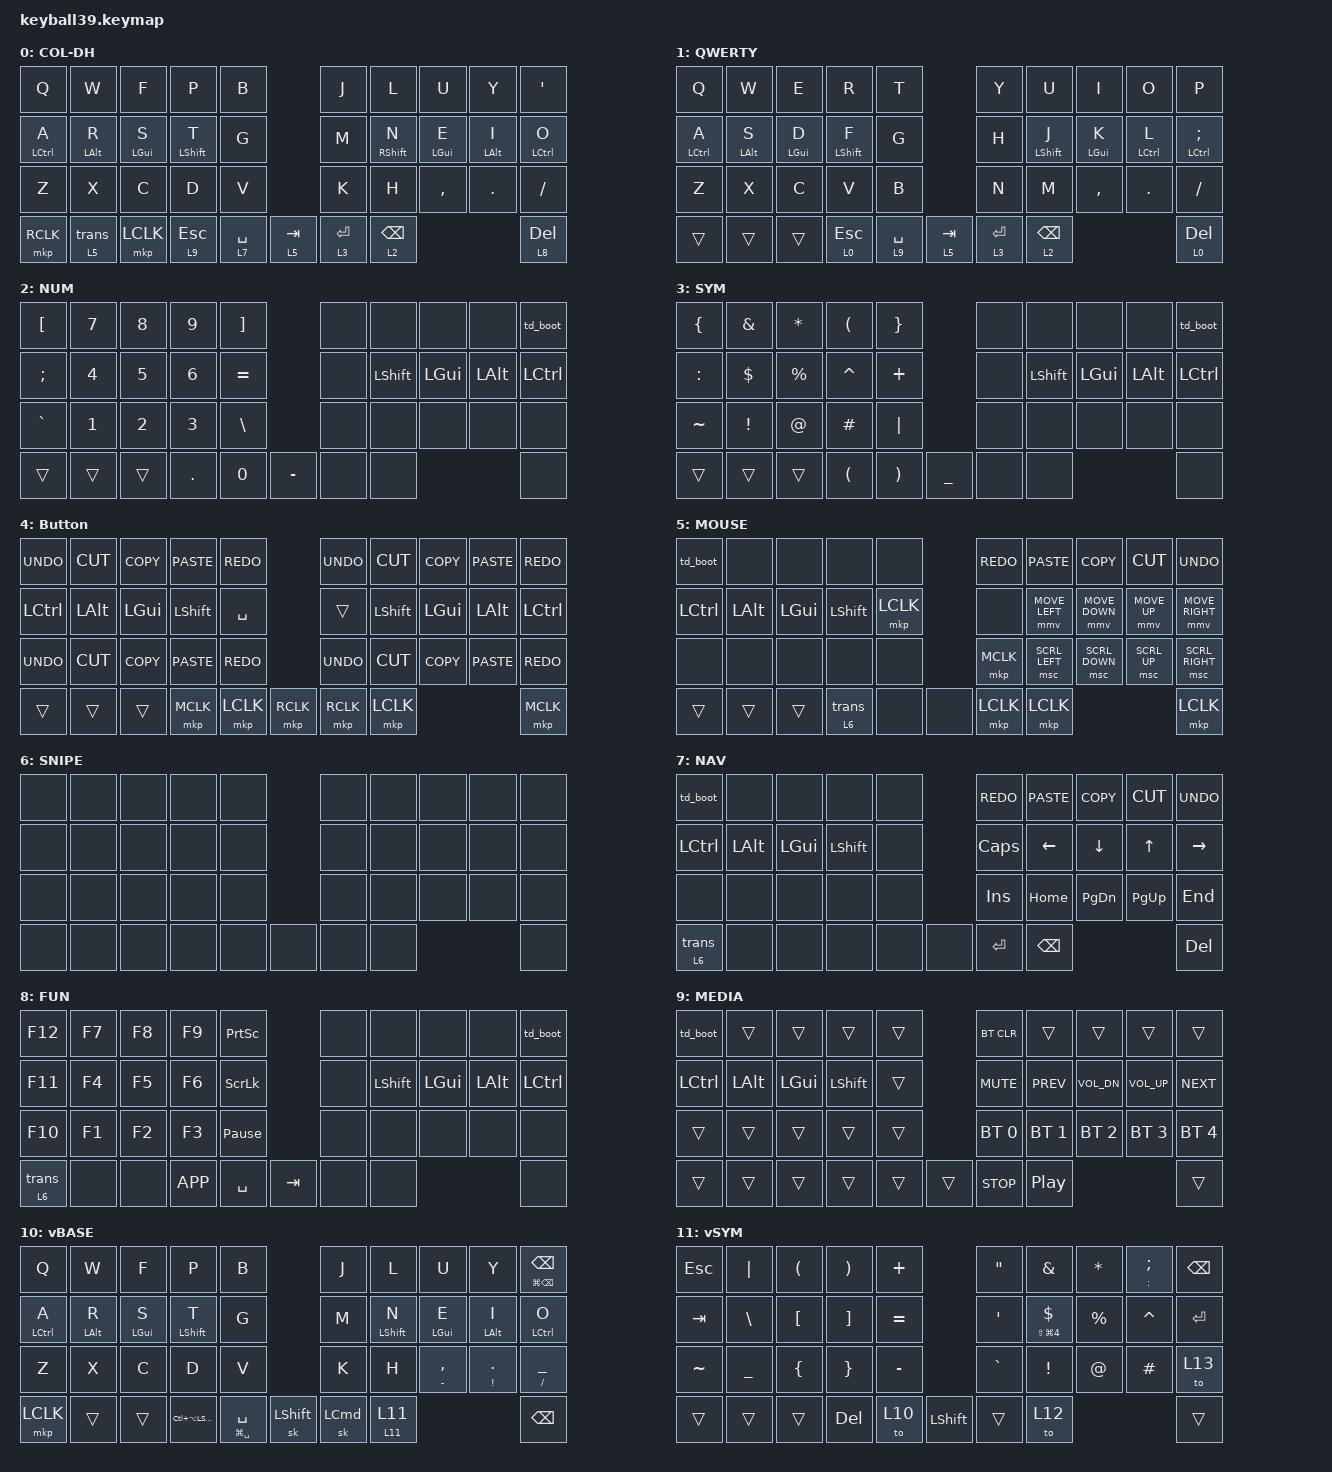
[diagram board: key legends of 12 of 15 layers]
//ZMK configs

#include <behaviors/mouse_keys.dtsi>
#include <dt-bindings/zmk/mouse.h>
#include <behaviors.dtsi>
#include <dt-bindings/zmk/bt.h>
#include <dt-bindings/zmk/keys.h>
#include <dt-bindings/zmk/pointing.h>

// Personal configs

#define HM_TAPPING_TERM 250
#define HM_TAPPING_TERM_FAST 180
#define HM_PRIOR_IDLE 120
#define XXX &none
#define ___ &trans
#define DEFAULT 0  // Colmak Mod-DH
#define QWERTY  1  // QWERTY Alternative
#define NUM     2  // Numbers and related symbols
#define SYM     3  // Symbols mapped similarly to numbers
#define BUTTON  4  // Button layer in conjunction with a mouse or input device
#define MOUSE   5  // Mouse layer also used as a scroll layer
#define SNIPE   6  // Snipe layer for more precise cursor control
#define NAV     7  // Navigation layer for arrow keys and navigation keys
#define FUN     8  // Function layer for function keys
#define MEDIA   9  // Media layer for media control keys

/* Global defaults */

#define QUICK_TAP_MS 175

&sk {
    release-after-ms = <900>;
    quick-release;
};

&sl { ignore-modifiers; };

&lt {
    flavor = "balanced";
    tapping-term-ms = <200>;
    quick-tap-ms = <QUICK_TAP_MS>;
};

/ {
    // custom shift using mod-morph 

    behaviors {
        bt_clr_dbl: bluetooth_clear {
            compatible = "zmk,behavior-tap-dance";
            label = "Clear bluetooth profile";
            #binding-cells = <0>;
            bindings = <&none>, <&bt BT_CLR>;
        };

        td_boot: double_tap_bootloader {
            compatible = "zmk,behavior-tap-dance";
            label = "Double Tap Bootloader";
            #binding-cells = <0>;
            bindings = <&none>, <&bootloader>;
        };

        ht_layertrans: ht_layertrans {
            compatible = "zmk,behavior-hold-tap";
            label = "Switches to Layer on Hold, Trans on Tap";
            bindings = <&mo>, <&trans>;

            #binding-cells = <2>;
            tapping-term-ms = <200>;
        };

        hrm_l: homerow_mod_left {
            compatible = "zmk,behavior-hold-tap";
            label = "Homerow Mod - Left";
            bindings = <&kp>, <&kp>;

            #binding-cells = <2>;
            tapping-term-ms = <250>;
            quick-tap-ms = <175>;
            require-prior-idle-ms = <120>;
            flavor = "balanced";
            hold-trigger-key-positions = <5 6 7 8 9 15 16 17 18 19 25 26 27 28 29 36 37 38 35 34 33 32 31 30>;
            hold-trigger-on-release;
        };

        hrm_r: homerow_mod_right {
            compatible = "zmk,behavior-hold-tap";
            label = "Homerow Mod - Right";
            bindings = <&kp>, <&kp>;

            #binding-cells = <2>;
            tapping-term-ms = <250>;
            quick-tap-ms = <175>;
            require-prior-idle-ms = <120>;
            flavor = "balanced";
            hold-trigger-on-release;
            hold-trigger-key-positions = <0 1 2 3 4 10 11 12 13 14 20 21 22 23 24 30 31 32 33 34 35 38 37 36>;
        };

        hrm_shift_l: homerow_mod_shift_left {
            compatible = "zmk,behavior-hold-tap";
            label = "Homerow Mod - Shift - Left";
            bindings = <&kp>, <&kp>;

            #binding-cells = <2>;
            tapping-term-ms = <180>;
            quick-tap-ms = <175>;
            require-prior-idle-ms = <120>;
            flavor = "balanced";
            hold-trigger-key-positions = <5 6 7 8 9 15 16 17 18 19 25 26 27 28 29 36 37 38 35 34 33 32 31 30>;
        };

        hrm_shift_r: homerow_mod_shift_right {
            compatible = "zmk,behavior-hold-tap";
            label = "Homerow Mod - Shift - Right";
            bindings = <&kp>, <&kp>;

            #binding-cells = <2>;
            tapping-term-ms = <180>;
            quick-tap-ms = <175>;
            require-prior-idle-ms = <120>;
            flavor = "balanced";
            hold-trigger-key-positions = <0 1 2 3 4 10 11 12 13 14 20 21 22 23 24 30 31 32 33 34 35 36 37 38>;
        };

        ht_holdto_tapsticky: ht_holdto_tapsticky {
            compatible = "zmk,behavior-hold-tap";
            label = "Hold Tap (to layer, sticky layer)";
            bindings = <&to>, <&sl>;

            #binding-cells = <2>;
            tapping-term-ms = <250>;
            flavor = "tap-preferred";
            quick-tap-ms = <175>;
            require-prior-idle-ms = <120>;
        };
    };

    keymap {
        compatible = "zmk,keymap";

        miryoku_alpha_colmak {
            label = "COL-DH";
            bindings = <
&kp Q           &kp W               &kp F          &kp P                  &kp B                                &kp J            &kp L                  &kp U          &kp Y          &kp APOS
&hrm_l LCTRL A  &hrm_l LALT R       &hrm_l LGUI S  &hrm_shift_l LSHIFT T  &kp G                                &kp M            &hrm_shift_r RSHIFT N  &hrm_r LGUI E  &hrm_r LALT I  &hrm_r LCTRL O
&kp Z           &kp X               &kp C          &kp D                  &kp V                                &kp K            &kp H                  &kp COMMA      &kp DOT        &kp FSLH
&mkp RCLK       &ht_layertrans 5 0  &mkp LCLK      &lt 9 ESCAPE           &lt 7 SPACE  &lt 5 TAB  &lt 3 ENTER  &lt 2 BACKSPACE                                                       &lt 8 DEL
            >;
        };

        miryoku_alpha_qwerty {
            label = "QWERTY";
            bindings = <
&kp Q           &kp W          &kp E          &kp R                  &kp T                                &kp Y            &kp U                  &kp I          &kp O           &kp P
&hrm_l LCTRL A  &hrm_l LALT S  &hrm_l LGUI D  &hrm_shift_l LSHIFT F  &kp G                                &kp H            &hrm_shift_r LSHIFT J  &hrm_r LGUI K  &hrm_r LCTRL L  &hrm_r LCTRL SEMICOLON
&kp Z           &kp X          &kp C          &kp V                  &kp B                                &kp N            &kp M                  &kp COMMA      &kp DOT         &kp FSLH
&trans          &trans         &trans         &lt 0 ESCAPE           &lt 9 SPACE  &lt 5 TAB  &lt 3 ENTER  &lt 2 BACKSPACE                                                        &lt 0 DEL
            >;
        };

        miryoku_num {
            label = "NUM";
            bindings = <
&kp LBKT   &kp N7  &kp N8  &kp N9   &kp RBKT                     &none  &none      &none     &none     &td_boot
&kp SEMI   &kp N4  &kp N5  &kp N6   &kp EQUAL                    &none  &kp LSHFT  &kp LGUI  &kp LALT  &kp LCTRL
&kp GRAVE  &kp N1  &kp N2  &kp N3   &kp BSLH                     &none  &none      &none     &none     &none
&trans     &trans  &trans  &kp DOT  &kp N0     &kp MINUS  &none  &none                                 &none
            >;
        };

        miryoku_sym {
            label = "SYM";
            bindings = <
&kp LBRC   &kp AMPS  &kp ASTRK  &kp LPAR   &kp RBRC                    &none  &none      &none     &none     &td_boot
&kp COLON  &kp DLLR  &kp PRCNT  &kp CARET  &kp PLUS                    &none  &kp LSHFT  &kp LGUI  &kp LALT  &kp LCTRL
&kp TILDE  &kp EXCL  &kp AT     &kp HASH   &kp PIPE                    &none  &none      &none     &none     &none
&trans     &trans    &trans     &kp LPAR   &kp RPAR  &kp UNDER  &none  &none                                 &none
            >;
        };

        miryoku_button {
            bindings = <
&kp K_UNDO  &kp K_CUT     &kp K_COPY  &kp K_PASTE  &kp K_REDO                        &kp K_UNDO  &kp K_CUT  &kp K_COPY  &kp K_PASTE   &kp K_REDO
&kp LCTRL   &kp LEFT_ALT  &kp LGUI    &kp LSHFT    &kp SPACE                         &trans      &kp LSHFT  &kp LGUI    &kp LEFT_ALT  &kp LCTRL
&kp K_UNDO  &kp K_CUT     &kp K_COPY  &kp K_PASTE  &kp K_REDO                        &kp K_UNDO  &kp K_CUT  &kp K_COPY  &kp K_PASTE   &kp K_REDO
&trans      &trans        &trans      &mkp MCLK    &mkp LCLK   &mkp RCLK  &mkp RCLK  &mkp LCLK                                        &mkp MCLK
            >;

            label = "Button";
        };

        miryoku_mouse {
            label = "MOUSE";
            bindings = <
&td_boot   &none         &none     &none               &none                        &kp K_REDO  &kp K_PASTE     &kp K_COPY      &kp K_CUT     &kp K_UNDO
&kp LCTRL  &kp LEFT_ALT  &kp LGUI  &kp LSHFT           &mkp LCLK                    &none       &mmv MOVE_LEFT  &mmv MOVE_DOWN  &mmv MOVE_UP  &mmv MOVE_RIGHT
&none      &none         &none     &none               &none                        &mkp MCLK   &msc SCRL_LEFT  &msc SCRL_DOWN  &msc SCRL_UP  &msc SCRL_RIGHT
&trans     &trans        &trans    &ht_layertrans 6 0  &none      &none  &mkp LCLK  &mkp LCLK                                                 &mkp LCLK
            >;
        };

        miryoku_snipe {
            label = "SNIPE";
            bindings = <
&none  &none  &none  &none  &none                &none  &none  &none  &none  &none
&none  &none  &none  &none  &none                &none  &none  &none  &none  &none
&none  &none  &none  &none  &none                &none  &none  &none  &none  &none
&none  &none  &none  &none  &none  &none  &none  &none                       &none
            >;
        };

        miryoku_nav {
            label = "NAV";
            bindings = <
&td_boot            &none         &none     &none      &none                  &kp K_REDO  &kp K_PASTE     &kp K_COPY  &kp K_CUT  &kp K_UNDO
&kp LCTRL           &kp LEFT_ALT  &kp LGUI  &kp LSHFT  &none                  &kp CAPS    &kp LEFT_ARROW  &kp DOWN    &kp UP     &kp RIGHT
&none               &none         &none     &none      &none                  &kp INS     &kp HOME        &kp PG_DN   &kp PG_UP  &kp END
&ht_layertrans 6 0  &none         &none     &none      &none  &none  &kp RET  &kp BSPC                                           &kp DEL
            >;
        };

        miryoku_fun {
            label = "FUN";
            bindings = <
&kp F12             &kp F7  &kp F8  &kp F9     &kp PSCRN                        &none  &none      &none     &none     &td_boot
&kp F11             &kp F4  &kp F5  &kp F6     &kp SLCK                         &none  &kp LSHFT  &kp LGUI  &kp LALT  &kp LCTRL
&kp F10             &kp F1  &kp F2  &kp F3     &kp PAUSE_BREAK                  &none  &none      &none     &none     &none
&ht_layertrans 6 0  &none   &none   &kp K_APP  &kp SPACE        &kp TAB  &none  &none                                 &none
            >;
        };

        miryoku_media {
            bindings = <
&td_boot   &trans        &trans    &trans     &trans                      &bt BT_CLR        &trans        &trans        &trans           &trans
&kp LCTRL  &kp LEFT_ALT  &kp LGUI  &kp LSHFT  &trans                      &kp K_MUTE        &kp C_PREV    &kp C_VOL_DN  &kp C_VOLUME_UP  &kp C_NEXT
&trans     &trans        &trans    &trans     &trans                      &bt BT_SEL 0      &bt BT_SEL 1  &bt BT_SEL 2  &bt BT_SEL 3     &bt BT_SEL 4
&trans     &trans        &trans    &trans     &trans  &trans  &kp C_STOP  &kp C_PLAY_PAUSE                                               &trans
            >;

            label = "MEDIA";
        };

        Vallack_Base {
            bindings = <
&kp Q           &kp W          &kp F          &kp P                 &kp B                                     &kp J                       &kp L                 &kp U            &kp Y                &mt LG(BACKSPACE) BACKSPACE
&hrm_l LCTRL A  &hrm_l LALT R  &hrm_l LGUI S  &hrm_shift_l LSHFT T  &kp G                                     &kp M                       &hrm_shift_r LSHFT N  &hrm_r LGUI E    &hrm_r LALT I        &hrm_r LCTRL O
&kp Z           &kp X          &kp C          &kp D                 &kp V                                     &kp K                       &kp H                 &mt MINUS COMMA  &mt EXCLAMATION DOT  &mt SLASH UNDER
&mkp LCLK       &trans         &trans         &kp LC(LA(LSHFT))     &mt LG(SPACE) SPACE  &sk LSHFT  &sk LCMD  &ht_holdto_tapsticky 11 11                                                              &kp BACKSPACE
            >;

            label = "vBASE";
        };

        Vallack_SYM {
            bindings = <
                &kp ESC    &kp PIPE        &kp LEFT_PARENTHESIS  &kp RIGHT_PARENTHESIS  &kp PLUS                      &kp DOUBLE_QUOTES  &kp AMPERSAND                &kp ASTERISK  &mt COLON SEMICOLON  &kp BACKSPACE
                &kp TAB    &kp BSLH        &kp LBKT              &kp RIGHT_BRACKET      &kp EQUAL                     &kp APOS           &mt LS(LG(NUMBER_4)) DOLLAR  &kp PERCENT   &kp CARET            &kp ENTER
                &kp TILDE  &kp UNDERSCORE  &kp LEFT_BRACE        &kp RIGHT_BRACE        &kp MINUS                     &kp GRAVE          &kp EXCL                     &kp AT        &kp HASH             &to 13
                &trans     &trans          &trans                &kp DEL                &to 10     &kp LSHFT  &trans  &to 12                                                                             &trans
            >;

            label = "vSYM";
        };

        Vallck_NUM {
            bindings = <

                &kp ESC     &kp C_PLAY_PAUSE    &kp C_PREV              &kp C_NEXT            &mt LS(LG(MINUS)) LS(MINUS)                  &mt LG(MINUS) MINUS  &mt F7 N7   &mt F8 N8   &mt F9 N9  &kp BSPC
                &kp TAB     &kp C_MUTE          &kp C_VOL_DN            &kp C_VOL_UP          &mt LS(LG(EQUAL)) EQUAL                      &mt EQUAL LG(EQUAL)  &mt F4 N4   &mt F5 N5   &mt F6 N6  &kp RET
                &to 13      &kp ASTERISK        &kp C_BRIGHTNESS_DEC    &kp C_BRIGHTNESS_INC  &kp DOT                                      &kp N0               &mt F1 N1   &mt F2 N2   &mt F3 N3  &to 13
                &trans      &trans              &trans                  &kp DEL               &to 10                       &trans  &trans  &trans                                                &trans
            >;

            label = "vNUM";
        };

        Vallack_NAV {
            bindings = <
                &trans  &trans  &trans  &trans      &trans                  &trans  &trans  &trans  &trans  &trans
                &trans  &trans  &trans  &trans      &trans                  &mt     &mt     &mt     &mt     &trans
                &trans  &trans  &trans  &trans      &trans                  &trans  &trans  &trans  &trans  &trans
                &trans  &trans  &trans  &kp DELETE  &to 10  &trans  &trans  &trans                          &trans
            >;

            label = "vNAV";
        };
        
        Vallack_KEY {
            bindings = <
                &trans  &trans  &trans  &trans      &trans                  &trans  &trans  &trans  &trans  &trans
                &trans  &trans  &trans  &trans      &trans                  &mt     &mt     &mt     &mt     &trans
                &trans  &trans  &trans  &trans      &trans                  &trans  &trans  &trans  &trans  &trans
                &trans  &trans  &trans  &kp DELETE  &to 10  &trans  &trans  &trans                          &trans
            >;

            label = "vKEY";
        };
    };
};
